VERSION "1.0.0"

NS_ :

BS_:

BU_: PCM PDM

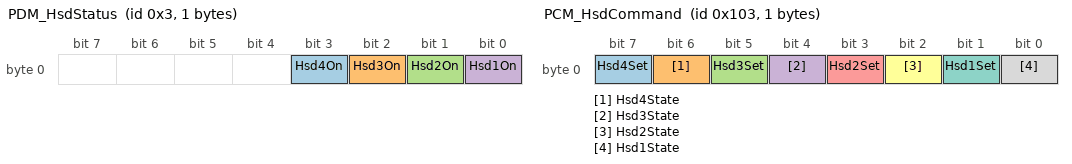
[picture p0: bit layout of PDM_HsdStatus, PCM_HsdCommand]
BO_ 3 PDM_HsdStatus: 1 PDM
 SG_ Hsd4On : 3|1@1+ (1,0) [0|1] "" Vector__XXX
 SG_ Hsd3On : 2|1@1+ (1,0) [0|1] "" Vector__XXX
 SG_ Hsd2On : 1|1@1+ (1,0) [0|1] "" Vector__XXX
 SG_ Hsd1On : 0|1@1+ (1,0) [0|1] "" Vector__XXX

BO_ 259 PCM_HsdCommand: 1 PCM
 SG_ Hsd4Set : 7|1@1+ (1,0) [0|1] ""  PDM
 SG_ Hsd4State : 6|1@1+ (1,0) [0|1] ""  PDM
 SG_ Hsd3Set : 5|1@1+ (1,0) [0|1] ""  PDM
 SG_ Hsd3State : 4|1@1+ (1,0) [0|1] ""  PDM
 SG_ Hsd2Set : 3|1@1+ (1,0) [0|1] ""  PDM
 SG_ Hsd2State : 2|1@1+ (1,0) [0|1] ""  PDM
 SG_ Hsd1Set : 1|1@1+ (1,0) [0|1] ""  PDM
 SG_ Hsd1State : 0|1@1+ (1,0) [0|1] ""  PDM

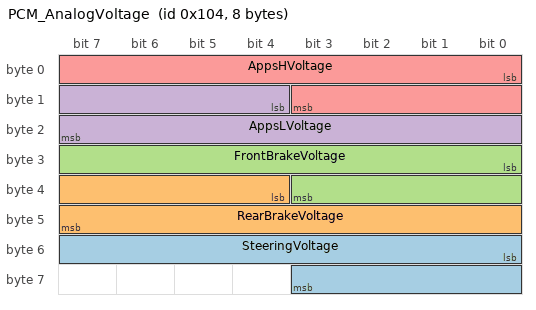
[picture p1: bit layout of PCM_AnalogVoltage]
BO_ 260 PCM_AnalogVoltage: 8 PCM
 SG_ SteeringVoltage : 48|12@1+ (0.001220703125,0) [0|5] "V" Vector__XXX
 SG_ RearBrakeVoltage : 36|12@1+ (0.001220703125,0) [0|5] "V" Vector__XXX
 SG_ FrontBrakeVoltage : 24|12@1+ (0.001220703125,0) [0|5] "V" Vector__XXX
 SG_ AppsLVoltage : 12|12@1+ (0.0008056640625,0) [0|3.3] "V" Vector__XXX
 SG_ AppsHVoltage : 0|12@1+ (0.001220703125,0) [0|5] "V" Vector__XXX

CM_ BO_ 3 "PDM-reported on/off state. Byte 0 bits 4 through 7 are reserved and transmitted as zero.";
CM_ BO_ 259 "Use the Set bits to choose which drivers to update. For each selected driver, a State of 1 turns it on and a State of 0 turns it off. All other drivers keep their current state.";
CM_ BO_ 260 "PCM-reported analog voltage for each sensor";

VAL_ 3 Hsd4On 0 "Off" 1 "On" ;
VAL_ 3 Hsd3On 0 "Off" 1 "On" ;
VAL_ 3 Hsd2On 0 "Off" 1 "On" ;
VAL_ 3 Hsd1On 0 "Off" 1 "On" ;
VAL_ 259 Hsd4Set 0 "DoNothing" 1 "Set" ;
VAL_ 259 Hsd4State 0 "Off" 1 "On" ;
VAL_ 259 Hsd3Set 0 "DoNothing" 1 "Set" ;
VAL_ 259 Hsd3State 0 "Off" 1 "On" ;
VAL_ 259 Hsd2Set 0 "DoNothing" 1 "Set" ;
VAL_ 259 Hsd2State 0 "Off" 1 "On" ;
VAL_ 259 Hsd1Set 0 "DoNothing" 1 "Set" ;
VAL_ 259 Hsd1State 0 "Off" 1 "On" ;
